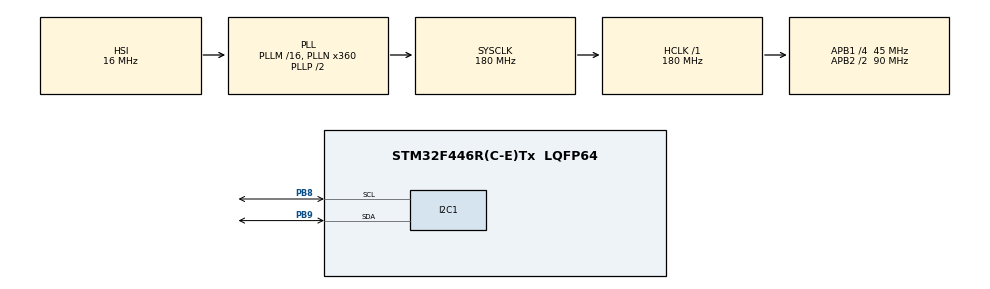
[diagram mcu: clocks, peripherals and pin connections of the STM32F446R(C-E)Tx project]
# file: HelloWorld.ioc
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Mcu.Family=STM32F4
Mcu.Name=STM32F446R(C-E)Tx
Mcu.Package=LQFP64
NVIC.PriorityGroup=NVIC_PRIORITYGROUP_4
PA13.Mode=Serial_Wire
PA13.Signal=SYS_JTMS-SWDIO
PA14.Mode=Serial_Wire
PA14.Signal=SYS_JTCK-SWCLK
PB8.Mode=I2C
PB8.Signal=I2C1_SCL
PB9.Mode=I2C
PB9.Signal=I2C1_SDA
ProjectManager.HeapSize=0x200
ProjectManager.StackSize=0x400
ProjectManager.TargetToolchain=STM32CubeIDE
RCC.AHBFreq_Value=180000000
RCC.APB1CLKDivider=RCC_HCLK_DIV4
RCC.APB1Freq_Value=45000000
RCC.APB1TimFreq_Value=90000000
RCC.APB2CLKDivider=RCC_HCLK_DIV2
RCC.APB2Freq_Value=90000000
RCC.APB2TimFreq_Value=180000000
RCC.CortexFreq_Value=180000000
RCC.HCLKFreq_Value=180000000
RCC.PLLN=360
RCC.SYSCLKFreq_VALUE=180000000
RCC.SYSCLKSource=RCC_SYSCLKSOURCE_PLLCLK
RCC.USBFreq_Value=180000000
RCC.VCOOutputFreq_Value=360000000
board=custom

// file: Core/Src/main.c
/* USER CODE BEGIN Header */
/**
  ******************************************************************************
  * @file           : main.c
  * @brief          : Main program body
  ******************************************************************************
  * @attention
  *
  * <h2><center>&copy; Copyright (c) 2022 STMicroelectronics.
  * All rights reserved.</center></h2>
  *
  * This software component is licensed by ST under BSD 3-Clause license,
  * the "License"; You may not use this file except in compliance with the
  * License. You may obtain a copy of the License at:
  *                        opensource.org/licenses/BSD-3-Clause
  *
  ******************************************************************************
  */
/* USER CODE END Header */
#include "main.h"

I2C_HandleTypeDef hi2c1;

/* USER CODE BEGIN PV */
uint32_t CounterSys, MyCounter;
/* USER CODE END PV */

void SystemClock_Config(void);
static void MX_GPIO_Init(void);
static void MX_I2C1_Init(void);

int main(void)
{

  /* MCU Configuration--------------------------------------------------------*/

  /* Reset of all peripherals, Initializes the Flash interface and the Systick. */
  HAL_Init();

  /* Configure the system clock */
  SystemClock_Config();

  /* Initialize all configured peripherals */
  MX_GPIO_Init();
  MX_I2C1_Init();

  /* Infinite loop */
  while (1)
  {

    /* USER CODE BEGIN 3 */
	  CounterSys = HAL_GetTick();
	  MyCounter++;
	  // Add a delay
	  HAL_Delay(1000);	// 1000 mS = 1 second
  }
  /* USER CODE END 3 */
}

void SystemClock_Config(void)
{
  RCC_OscInitTypeDef RCC_OscInitStruct = {0};
  RCC_ClkInitTypeDef RCC_ClkInitStruct = {0};

  /** Configure the main internal regulator output voltage
  */
  __HAL_RCC_PWR_CLK_ENABLE();
  __HAL_PWR_VOLTAGESCALING_CONFIG(PWR_REGULATOR_VOLTAGE_SCALE1);
  /** Initializes the RCC Oscillators according to the specified parameters
  * in the RCC_OscInitTypeDef structure.
  */
  RCC_OscInitStruct.OscillatorType = RCC_OSCILLATORTYPE_HSI;
  RCC_OscInitStruct.HSIState = RCC_HSI_ON;
  RCC_OscInitStruct.HSICalibrationValue = RCC_HSICALIBRATION_DEFAULT;
  RCC_OscInitStruct.PLL.PLLState = RCC_PLL_ON;
  RCC_OscInitStruct.PLL.PLLSource = RCC_PLLSOURCE_HSI;
  RCC_OscInitStruct.PLL.PLLM = 16;
  RCC_OscInitStruct.PLL.PLLN = 360;
  RCC_OscInitStruct.PLL.PLLP = RCC_PLLP_DIV2;
  RCC_OscInitStruct.PLL.PLLQ = 2;
  RCC_OscInitStruct.PLL.PLLR = 2;
  if (HAL_RCC_OscConfig(&RCC_OscInitStruct) != HAL_OK)
  {
    Error_Handler();
  }
  /** Activate the Over-Drive mode
  */
  if (HAL_PWREx_EnableOverDrive() != HAL_OK)
  {
    Error_Handler();
  }
  /** Initializes the CPU, AHB and APB buses clocks
  */
  RCC_ClkInitStruct.ClockType = RCC_CLOCKTYPE_HCLK|RCC_CLOCKTYPE_SYSCLK
                              |RCC_CLOCKTYPE_PCLK1|RCC_CLOCKTYPE_PCLK2;
  RCC_ClkInitStruct.SYSCLKSource = RCC_SYSCLKSOURCE_PLLCLK;
  RCC_ClkInitStruct.AHBCLKDivider = RCC_SYSCLK_DIV1;
  RCC_ClkInitStruct.APB1CLKDivider = RCC_HCLK_DIV4;
  RCC_ClkInitStruct.APB2CLKDivider = RCC_HCLK_DIV2;

  if (HAL_RCC_ClockConfig(&RCC_ClkInitStruct, FLASH_LATENCY_5) != HAL_OK)
  {
    Error_Handler();
  }
}

static void MX_I2C1_Init(void)
{

  hi2c1.Instance = I2C1;
  hi2c1.Init.ClockSpeed = 100000;
  hi2c1.Init.DutyCycle = I2C_DUTYCYCLE_2;
  hi2c1.Init.OwnAddress1 = 0;
  hi2c1.Init.AddressingMode = I2C_ADDRESSINGMODE_7BIT;
  hi2c1.Init.DualAddressMode = I2C_DUALADDRESS_DISABLE;
  hi2c1.Init.OwnAddress2 = 0;
  hi2c1.Init.GeneralCallMode = I2C_GENERALCALL_DISABLE;
  hi2c1.Init.NoStretchMode = I2C_NOSTRETCH_DISABLE;
  if (HAL_I2C_Init(&hi2c1) != HAL_OK)
  {
    Error_Handler();
  }

}

static void MX_GPIO_Init(void)
{

  /* GPIO Ports Clock Enable */
  __HAL_RCC_GPIOA_CLK_ENABLE();
  __HAL_RCC_GPIOB_CLK_ENABLE();

}

void Error_Handler(void)
{
  __disable_irq();
  while (1)
  {
  }
}

/************************ (C) COPYRIGHT STMicroelectronics *****END OF FILE****/
